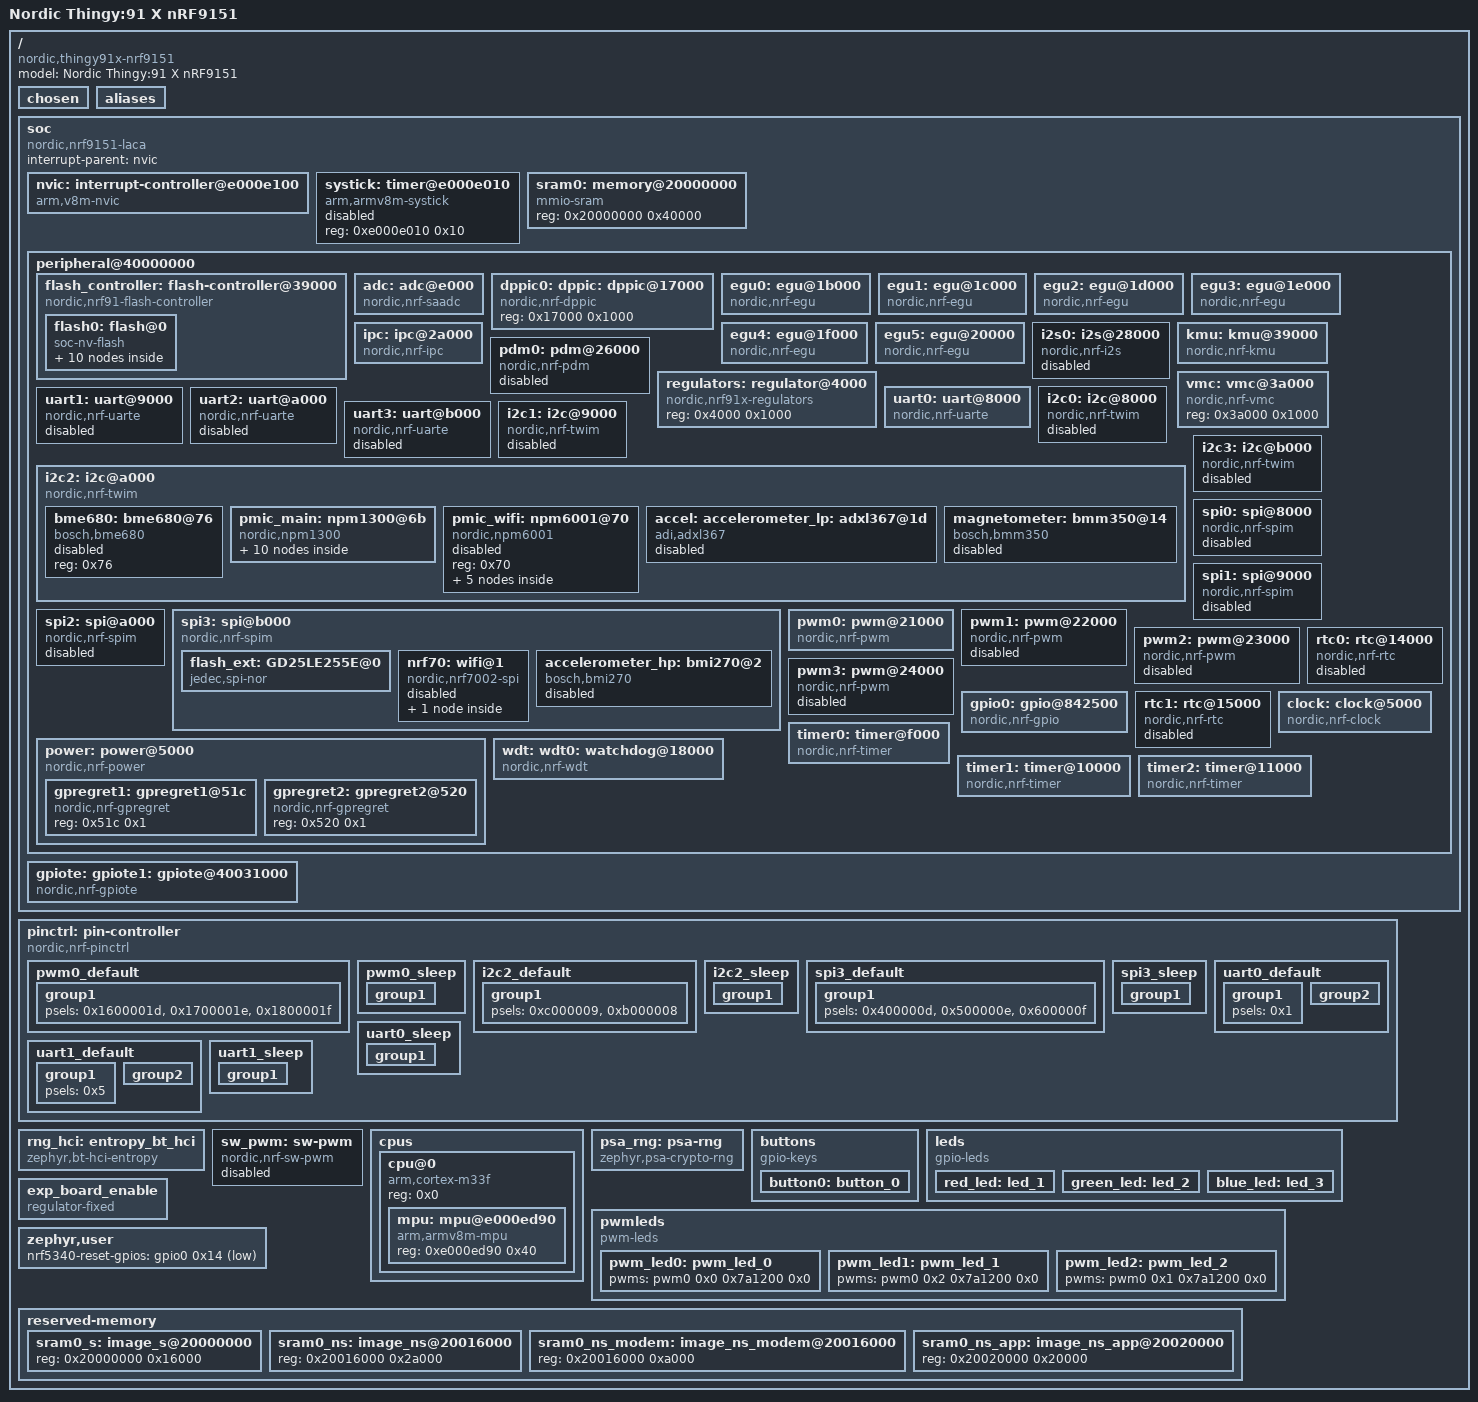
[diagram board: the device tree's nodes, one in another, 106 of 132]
/dts-v1/;

/* node '/' defined in zephyr/dts/common/skeleton.dtsi:9 */
/ {
	#address-cells = < 0x1 >;                /* in zephyr/dts/common/skeleton.dtsi:10 */
	#size-cells = < 0x1 >;                   /* in zephyr/dts/common/skeleton.dtsi:11 */
	model = "Nordic Thingy:91 X nRF9151";    /* in nrf/boards/nordic/thingy91x/thingy91x_nrf9151_common.dtsi:10 */
	compatible = "nordic,thingy91x-nrf9151"; /* in nrf/boards/nordic/thingy91x/thingy91x_nrf9151_common.dtsi:11 */

	/* node '/chosen' defined in zephyr/dts/common/skeleton.dtsi:12 */
	chosen {
		zephyr,entropy = &psa_rng;                   /* in zephyr/dts/arm/nordic/nrf91ns.dtsi:31 */
		zephyr,flash-controller = &flash_controller; /* in zephyr/dts/arm/nordic/nrf91ns.dtsi:32 */
		zephyr,console = &uart0;                     /* in nrf/boards/nordic/thingy91x/thingy91x_nrf9151_common.dtsi:14 */
		zephyr,shell-uart = &uart0;                  /* in nrf/boards/nordic/thingy91x/thingy91x_nrf9151_common.dtsi:15 */
		zephyr,uart-mcumgr = &uart0;                 /* in nrf/boards/nordic/thingy91x/thingy91x_nrf9151_common.dtsi:16 */
		nordic,pm-ext-flash = &flash_ext;            /* in nrf/boards/nordic/thingy91x/thingy91x_nrf9151_common.dtsi:17 */
		zephyr,flash = &flash0;                      /* in nrf/boards/nordic/thingy91x/thingy91x_nrf9151_ns.dts:12 */
		zephyr,sram = &sram0_ns_app;                 /* in nrf/boards/nordic/thingy91x/thingy91x_nrf9151_ns.dts:13 */
		zephyr,code-partition = &slot0_ns_partition; /* in nrf/boards/nordic/thingy91x/thingy91x_nrf9151_ns.dts:14 */
		zephyr,wifi = &nordic_wlan0;                 /* in nrf/boards/nordic/thingy91x/thingy91x_nrf9151_ns.dts:15 */
	};

	/* node '/aliases' defined in zephyr/dts/common/skeleton.dtsi:13 */
	aliases {
		sw0 = &button0;             /* in nrf/boards/nordic/thingy91x/thingy91x_nrf9151_common.dtsi:70 */
		led0 = &red_led;            /* in nrf/boards/nordic/thingy91x/thingy91x_nrf9151_common.dtsi:71 */
		led1 = &green_led;          /* in nrf/boards/nordic/thingy91x/thingy91x_nrf9151_common.dtsi:72 */
		led2 = &blue_led;           /* in nrf/boards/nordic/thingy91x/thingy91x_nrf9151_common.dtsi:73 */
		pwm-led0 = &pwm_led0;       /* in nrf/boards/nordic/thingy91x/thingy91x_nrf9151_common.dtsi:74 */
		pwm-led1 = &pwm_led1;       /* in nrf/boards/nordic/thingy91x/thingy91x_nrf9151_common.dtsi:75 */
		pwm-led2 = &pwm_led2;       /* in nrf/boards/nordic/thingy91x/thingy91x_nrf9151_common.dtsi:76 */
		rgb-pwm = &pwm0;            /* in nrf/boards/nordic/thingy91x/thingy91x_nrf9151_common.dtsi:77 */
		mcuboot-button0 = &button0; /* in nrf/boards/nordic/thingy91x/thingy91x_nrf9151_common.dtsi:78 */
		spi-flash0 = &flash_ext;    /* in nrf/boards/nordic/thingy91x/thingy91x_nrf9151_common.dtsi:79 */
	};

	/* node '/soc' defined in zephyr/dts/arm/armv8-m.dtsi:6 */
	soc {
		#address-cells = < 0x1 >;           /* in zephyr/dts/arm/armv8-m.dtsi:7 */
		#size-cells = < 0x1 >;              /* in zephyr/dts/arm/armv8-m.dtsi:8 */
		compatible = "nordic,nrf9151-laca",
		             "nordic,nrf9120",
		             "nordic,nrf91",
		             "simple-bus";          /* in zephyr/dts/arm/nordic/nrf9151ns_laca.dtsi:20 */
		interrupt-parent = < &nvic >;       /* in zephyr/dts/arm/armv8-m.dtsi:10 */
		ranges;                             /* in zephyr/dts/arm/armv8-m.dtsi:11 */

		/* node '/soc/interrupt-controller@e000e100' defined in zephyr/dts/arm/armv8-m.dtsi:13 */
		nvic: interrupt-controller@e000e100 {
			#address-cells = < 0x1 >;            /* in zephyr/dts/arm/armv8-m.dtsi:14 */
			compatible = "arm,v8m-nvic";         /* in zephyr/dts/arm/armv8-m.dtsi:15 */
			reg = < 0xe000e100 0xc00 >;          /* in zephyr/dts/arm/armv8-m.dtsi:16 */
			interrupt-controller;                /* in zephyr/dts/arm/armv8-m.dtsi:17 */
			#interrupt-cells = < 0x2 >;          /* in zephyr/dts/arm/armv8-m.dtsi:18 */
			arm,num-irq-priority-bits = < 0x3 >; /* in zephyr/dts/arm/nordic/nrf91ns.dtsi:70 */
			phandle = < 0x1 >;                   /* in zephyr/dts/arm/armv8-m.dtsi:10 */
		};

		/* node '/soc/timer@e000e010' defined in zephyr/dts/arm/armv8-m.dtsi:21 */
		systick: timer@e000e010 {
			compatible = "arm,armv8m-systick"; /* in zephyr/dts/arm/armv8-m.dtsi:22 */
			reg = < 0xe000e010 0x10 >;         /* in zephyr/dts/arm/armv8-m.dtsi:23 */
			status = "disabled";               /* in zephyr/dts/arm/nordic/nrf91ns.dtsi:75 */
		};

		/* node '/soc/memory@20000000' defined in zephyr/dts/arm/nordic/nrf91ns.dtsi:36 */
		sram0: memory@20000000 {
			compatible = "mmio-sram";     /* in zephyr/dts/arm/nordic/nrf91ns.dtsi:37 */
			reg = < 0x20000000 0x40000 >; /* in zephyr/dts/arm/nordic/nrf9151ns_laca.dtsi:15 */
		};

		/* node '/soc/peripheral@40000000' defined in zephyr/dts/arm/nordic/nrf91ns.dtsi:40 */
		peripheral@40000000 {
			#address-cells = < 0x1 >;               /* in zephyr/dts/arm/nordic/nrf91ns.dtsi:41 */
			#size-cells = < 0x1 >;                  /* in zephyr/dts/arm/nordic/nrf91ns.dtsi:42 */
			ranges = < 0x0 0x40000000 0x10000000 >; /* in zephyr/dts/arm/nordic/nrf91ns.dtsi:43 */

			/* node '/soc/peripheral@40000000/flash-controller@39000' defined in zephyr/dts/arm/nordic/nrf91_peripherals.dtsi:7 */
			flash_controller: flash-controller@39000 {
				compatible = "nordic,nrf91-flash-controller"; /* in zephyr/dts/arm/nordic/nrf91_peripherals.dtsi:8 */
				reg = < 0x39000 0x1000 >;                     /* in zephyr/dts/arm/nordic/nrf91_peripherals.dtsi:9 */
				partial-erase;                                /* in zephyr/dts/arm/nordic/nrf91_peripherals.dtsi:10 */
				#address-cells = < 0x1 >;                     /* in zephyr/dts/arm/nordic/nrf91_peripherals.dtsi:12 */
				#size-cells = < 0x1 >;                        /* in zephyr/dts/arm/nordic/nrf91_peripherals.dtsi:13 */

				/* node '/soc/peripheral@40000000/flash-controller@39000/flash@0' defined in zephyr/dts/arm/nordic/nrf91_peripherals.dtsi:16 */
				flash0: flash@0 {
					compatible = "soc-nv-flash";   /* in zephyr/dts/arm/nordic/nrf91_peripherals.dtsi:17 */
					erase-block-size = < 0x1000 >; /* in zephyr/dts/arm/nordic/nrf91_peripherals.dtsi:18 */
					write-block-size = < 0x4 >;    /* in zephyr/dts/arm/nordic/nrf91_peripherals.dtsi:19 */
					reg = < 0x0 0x100000 >;        /* in zephyr/dts/arm/nordic/nrf9151ns_laca.dtsi:11 */

					/* node '/soc/peripheral@40000000/flash-controller@39000/flash@0/partitions' defined in zephyr/dts/vendor/nordic/nrf91xx_partition.dtsi:27 */
					partitions {
						compatible = "fixed-partitions"; /* in zephyr/dts/vendor/nordic/nrf91xx_partition.dtsi:28 */
						#address-cells = < 0x1 >;        /* in zephyr/dts/vendor/nordic/nrf91xx_partition.dtsi:29 */
						#size-cells = < 0x1 >;           /* in zephyr/dts/vendor/nordic/nrf91xx_partition.dtsi:30 */

						/* node '/soc/peripheral@40000000/flash-controller@39000/flash@0/partitions/partition@0' defined in zephyr/dts/vendor/nordic/nrf91xx_partition.dtsi:32 */
						boot_partition: partition@0 {
							label = "mcuboot";     /* in zephyr/dts/vendor/nordic/nrf91xx_partition.dtsi:33 */
							reg = < 0x0 0x10000 >; /* in zephyr/dts/vendor/nordic/nrf91xx_partition.dtsi:34 */
						};

						/* node '/soc/peripheral@40000000/flash-controller@39000/flash@0/partitions/partition@10000' defined in zephyr/dts/vendor/nordic/nrf91xx_partition.dtsi:37 */
						slot0_partition: partition@10000 {
							label = "image-0";         /* in zephyr/dts/vendor/nordic/nrf91xx_partition.dtsi:38 */
							reg = < 0x10000 0x40000 >; /* in zephyr/dts/vendor/nordic/nrf91xx_partition.dtsi:39 */
						};

						/* node '/soc/peripheral@40000000/flash-controller@39000/flash@0/partitions/partition@50000' defined in zephyr/dts/vendor/nordic/nrf91xx_partition.dtsi:42 */
						slot0_ns_partition: partition@50000 {
							label = "image-0-nonsecure"; /* in zephyr/dts/vendor/nordic/nrf91xx_partition.dtsi:43 */
							reg = < 0x50000 0x30000 >;   /* in zephyr/dts/vendor/nordic/nrf91xx_partition.dtsi:44 */
						};

						/* node '/soc/peripheral@40000000/flash-controller@39000/flash@0/partitions/partition@80000' defined in zephyr/dts/vendor/nordic/nrf91xx_partition.dtsi:47 */
						slot1_partition: partition@80000 {
							label = "image-1";         /* in zephyr/dts/vendor/nordic/nrf91xx_partition.dtsi:48 */
							reg = < 0x80000 0x40000 >; /* in zephyr/dts/vendor/nordic/nrf91xx_partition.dtsi:49 */
						};

						/* node '/soc/peripheral@40000000/flash-controller@39000/flash@0/partitions/partition@c0000' defined in zephyr/dts/vendor/nordic/nrf91xx_partition.dtsi:52 */
						slot1_ns_partition: partition@c0000 {
							label = "image-1-nonsecure"; /* in zephyr/dts/vendor/nordic/nrf91xx_partition.dtsi:53 */
							reg = < 0xc0000 0x30000 >;   /* in zephyr/dts/vendor/nordic/nrf91xx_partition.dtsi:54 */
						};

						/* node '/soc/peripheral@40000000/flash-controller@39000/flash@0/partitions/partition@f0000' defined in zephyr/dts/vendor/nordic/nrf91xx_partition.dtsi:57 */
						tfm_ps_partition: partition@f0000 {
							label = "tfm-ps";         /* in zephyr/dts/vendor/nordic/nrf91xx_partition.dtsi:58 */
							reg = < 0xf0000 0x4000 >; /* in zephyr/dts/vendor/nordic/nrf91xx_partition.dtsi:59 */
						};

						/* node '/soc/peripheral@40000000/flash-controller@39000/flash@0/partitions/partition@f4000' defined in zephyr/dts/vendor/nordic/nrf91xx_partition.dtsi:62 */
						tfm_its_partition: partition@f4000 {
							label = "tfm-its";        /* in zephyr/dts/vendor/nordic/nrf91xx_partition.dtsi:63 */
							reg = < 0xf4000 0x2000 >; /* in zephyr/dts/vendor/nordic/nrf91xx_partition.dtsi:64 */
						};

						/* node '/soc/peripheral@40000000/flash-controller@39000/flash@0/partitions/partition@f6000' defined in zephyr/dts/vendor/nordic/nrf91xx_partition.dtsi:67 */
						tfm_otp_partition: partition@f6000 {
							label = "tfm-otp";        /* in zephyr/dts/vendor/nordic/nrf91xx_partition.dtsi:68 */
							reg = < 0xf6000 0x2000 >; /* in zephyr/dts/vendor/nordic/nrf91xx_partition.dtsi:69 */
						};

						/* node '/soc/peripheral@40000000/flash-controller@39000/flash@0/partitions/partition@f8000' defined in zephyr/dts/vendor/nordic/nrf91xx_partition.dtsi:72 */
						storage_partition: partition@f8000 {
							label = "storage";        /* in zephyr/dts/vendor/nordic/nrf91xx_partition.dtsi:73 */
							reg = < 0xf8000 0x8000 >; /* in zephyr/dts/vendor/nordic/nrf91xx_partition.dtsi:74 */
						};
					};
				};
			};

			/* node '/soc/peripheral@40000000/adc@e000' defined in zephyr/dts/arm/nordic/nrf91_peripherals.dtsi:23 */
			adc: adc@e000 {
				compatible = "nordic,nrf-saadc"; /* in zephyr/dts/arm/nordic/nrf91_peripherals.dtsi:24 */
				reg = < 0xe000 0x1000 >;         /* in zephyr/dts/arm/nordic/nrf91_peripherals.dtsi:25 */
				interrupts = < 0xe 0x1 >;        /* in zephyr/dts/arm/nordic/nrf91_peripherals.dtsi:26 */
				status = "okay";                 /* in nrf/boards/nordic/thingy91x/thingy91x_nrf9151_common.dtsi:84 */
				#io-channel-cells = < 0x1 >;     /* in zephyr/dts/arm/nordic/nrf91_peripherals.dtsi:28 */
				zephyr,pm-device-runtime-auto;   /* in zephyr/dts/arm/nordic/nrf91_peripherals.dtsi:29 */
			};

			/* node '/soc/peripheral@40000000/dppic@17000' defined in zephyr/dts/arm/nordic/nrf91_peripherals.dtsi:32 */
			dppic0: dppic: dppic@17000 {
				compatible = "nordic,nrf-dppic"; /* in zephyr/dts/arm/nordic/nrf91_peripherals.dtsi:33 */
				reg = < 0x17000 0x1000 >;        /* in zephyr/dts/arm/nordic/nrf91_peripherals.dtsi:34 */
				status = "okay";                 /* in zephyr/dts/arm/nordic/nrf91_peripherals.dtsi:35 */
			};

			/* node '/soc/peripheral@40000000/egu@1b000' defined in zephyr/dts/arm/nordic/nrf91_peripherals.dtsi:38 */
			egu0: egu@1b000 {
				compatible = "nordic,nrf-egu"; /* in zephyr/dts/arm/nordic/nrf91_peripherals.dtsi:39 */
				reg = < 0x1b000 0x1000 >;      /* in zephyr/dts/arm/nordic/nrf91_peripherals.dtsi:40 */
				interrupts = < 0x1b 0x1 >;     /* in zephyr/dts/arm/nordic/nrf91_peripherals.dtsi:41 */
				status = "okay";               /* in zephyr/dts/arm/nordic/nrf91_peripherals.dtsi:42 */
			};

			/* node '/soc/peripheral@40000000/egu@1c000' defined in zephyr/dts/arm/nordic/nrf91_peripherals.dtsi:45 */
			egu1: egu@1c000 {
				compatible = "nordic,nrf-egu"; /* in zephyr/dts/arm/nordic/nrf91_peripherals.dtsi:46 */
				reg = < 0x1c000 0x1000 >;      /* in zephyr/dts/arm/nordic/nrf91_peripherals.dtsi:47 */
				interrupts = < 0x1c 0x1 >;     /* in zephyr/dts/arm/nordic/nrf91_peripherals.dtsi:48 */
				status = "okay";               /* in zephyr/dts/arm/nordic/nrf91_peripherals.dtsi:49 */
			};

			/* node '/soc/peripheral@40000000/egu@1d000' defined in zephyr/dts/arm/nordic/nrf91_peripherals.dtsi:52 */
			egu2: egu@1d000 {
				compatible = "nordic,nrf-egu"; /* in zephyr/dts/arm/nordic/nrf91_peripherals.dtsi:53 */
				reg = < 0x1d000 0x1000 >;      /* in zephyr/dts/arm/nordic/nrf91_peripherals.dtsi:54 */
				interrupts = < 0x1d 0x1 >;     /* in zephyr/dts/arm/nordic/nrf91_peripherals.dtsi:55 */
				status = "okay";               /* in zephyr/dts/arm/nordic/nrf91_peripherals.dtsi:56 */
			};

			/* node '/soc/peripheral@40000000/egu@1e000' defined in zephyr/dts/arm/nordic/nrf91_peripherals.dtsi:59 */
			egu3: egu@1e000 {
				compatible = "nordic,nrf-egu"; /* in zephyr/dts/arm/nordic/nrf91_peripherals.dtsi:60 */
				reg = < 0x1e000 0x1000 >;      /* in zephyr/dts/arm/nordic/nrf91_peripherals.dtsi:61 */
				interrupts = < 0x1e 0x1 >;     /* in zephyr/dts/arm/nordic/nrf91_peripherals.dtsi:62 */
				status = "okay";               /* in zephyr/dts/arm/nordic/nrf91_peripherals.dtsi:63 */
			};

			/* node '/soc/peripheral@40000000/egu@1f000' defined in zephyr/dts/arm/nordic/nrf91_peripherals.dtsi:66 */
			egu4: egu@1f000 {
				compatible = "nordic,nrf-egu"; /* in zephyr/dts/arm/nordic/nrf91_peripherals.dtsi:67 */
				reg = < 0x1f000 0x1000 >;      /* in zephyr/dts/arm/nordic/nrf91_peripherals.dtsi:68 */
				interrupts = < 0x1f 0x1 >;     /* in zephyr/dts/arm/nordic/nrf91_peripherals.dtsi:69 */
				status = "okay";               /* in zephyr/dts/arm/nordic/nrf91_peripherals.dtsi:70 */
			};

			/* node '/soc/peripheral@40000000/egu@20000' defined in zephyr/dts/arm/nordic/nrf91_peripherals.dtsi:73 */
			egu5: egu@20000 {
				compatible = "nordic,nrf-egu"; /* in zephyr/dts/arm/nordic/nrf91_peripherals.dtsi:74 */
				reg = < 0x20000 0x1000 >;      /* in zephyr/dts/arm/nordic/nrf91_peripherals.dtsi:75 */
				interrupts = < 0x20 0x1 >;     /* in zephyr/dts/arm/nordic/nrf91_peripherals.dtsi:76 */
				status = "okay";               /* in zephyr/dts/arm/nordic/nrf91_peripherals.dtsi:77 */
			};

			/* node '/soc/peripheral@40000000/ipc@2a000' defined in zephyr/dts/arm/nordic/nrf91_peripherals.dtsi:80 */
			ipc: ipc@2a000 {
				compatible = "nordic,nrf-ipc"; /* in zephyr/dts/arm/nordic/nrf91_peripherals.dtsi:81 */
				reg = < 0x2a000 0x1000 >;      /* in zephyr/dts/arm/nordic/nrf91_peripherals.dtsi:82 */
				interrupts = < 0x2a 0x1 >;     /* in zephyr/dts/arm/nordic/nrf91_peripherals.dtsi:83 */
				status = "okay";               /* in zephyr/dts/arm/nordic/nrf91_peripherals.dtsi:84 */
			};

			/* node '/soc/peripheral@40000000/i2s@28000' defined in zephyr/dts/arm/nordic/nrf91_peripherals.dtsi:87 */
			i2s0: i2s@28000 {
				compatible = "nordic,nrf-i2s"; /* in zephyr/dts/arm/nordic/nrf91_peripherals.dtsi:88 */
				#address-cells = < 0x1 >;      /* in zephyr/dts/arm/nordic/nrf91_peripherals.dtsi:89 */
				#size-cells = < 0x0 >;         /* in zephyr/dts/arm/nordic/nrf91_peripherals.dtsi:90 */
				reg = < 0x28000 0x1000 >;      /* in zephyr/dts/arm/nordic/nrf91_peripherals.dtsi:91 */
				interrupts = < 0x28 0x1 >;     /* in zephyr/dts/arm/nordic/nrf91_peripherals.dtsi:92 */
				status = "disabled";           /* in zephyr/dts/arm/nordic/nrf91_peripherals.dtsi:93 */
			};

			/* node '/soc/peripheral@40000000/kmu@39000' defined in zephyr/dts/arm/nordic/nrf91_peripherals.dtsi:96 */
			kmu: kmu@39000 {
				compatible = "nordic,nrf-kmu"; /* in zephyr/dts/arm/nordic/nrf91_peripherals.dtsi:97 */
				reg = < 0x39000 0x1000 >;      /* in zephyr/dts/arm/nordic/nrf91_peripherals.dtsi:98 */
				interrupts = < 0x39 0x1 >;     /* in zephyr/dts/arm/nordic/nrf91_peripherals.dtsi:99 */
				status = "okay";               /* in zephyr/dts/arm/nordic/nrf91_peripherals.dtsi:100 */
			};

			/* node '/soc/peripheral@40000000/pdm@26000' defined in zephyr/dts/arm/nordic/nrf91_peripherals.dtsi:103 */
			pdm0: pdm@26000 {
				compatible = "nordic,nrf-pdm"; /* in zephyr/dts/arm/nordic/nrf91_peripherals.dtsi:104 */
				reg = < 0x26000 0x1000 >;      /* in zephyr/dts/arm/nordic/nrf91_peripherals.dtsi:105 */
				interrupts = < 0x26 0x1 >;     /* in zephyr/dts/arm/nordic/nrf91_peripherals.dtsi:106 */
				status = "disabled";           /* in zephyr/dts/arm/nordic/nrf91_peripherals.dtsi:107 */
			};

			/* node '/soc/peripheral@40000000/regulator@4000' defined in zephyr/dts/arm/nordic/nrf91_peripherals.dtsi:110 */
			regulators: regulator@4000 {
				compatible = "nordic,nrf91x-regulators"; /* in zephyr/dts/arm/nordic/nrf91_peripherals.dtsi:111 */
				reg = < 0x4000 0x1000 >;                 /* in zephyr/dts/arm/nordic/nrf91_peripherals.dtsi:112 */
				status = "okay";                         /* in zephyr/dts/arm/nordic/nrf91_peripherals.dtsi:113 */
			};

			/* node '/soc/peripheral@40000000/vmc@3a000' defined in zephyr/dts/arm/nordic/nrf91_peripherals.dtsi:116 */
			vmc: vmc@3a000 {
				compatible = "nordic,nrf-vmc"; /* in zephyr/dts/arm/nordic/nrf91_peripherals.dtsi:117 */
				reg = < 0x3a000 0x1000 >;      /* in zephyr/dts/arm/nordic/nrf91_peripherals.dtsi:118 */
				status = "okay";               /* in zephyr/dts/arm/nordic/nrf91_peripherals.dtsi:119 */
			};

			/* node '/soc/peripheral@40000000/uart@8000' defined in zephyr/dts/arm/nordic/nrf91_peripherals.dtsi:122 */
			uart0: uart@8000 {
				compatible = "nordic,nrf-uarte"; /* in nrf/boards/nordic/thingy91x/thingy91x_nrf9151_common.dtsi:164 */
				reg = < 0x8000 0x1000 >;         /* in zephyr/dts/arm/nordic/nrf91_peripherals.dtsi:124 */
				interrupts = < 0x8 0x1 >;        /* in zephyr/dts/arm/nordic/nrf91_peripherals.dtsi:125 */
				status = "okay";                 /* in nrf/boards/nordic/thingy91x/thingy91x_nrf9151_common.dtsi:166 */
				current-speed = < 0x1c200 >;     /* in nrf/boards/nordic/thingy91x/thingy91x_nrf9151_common.dtsi:165 */
				pinctrl-0 = < &uart0_default >;  /* in nrf/boards/nordic/thingy91x/thingy91x_nrf9151_common.dtsi:167 */
				pinctrl-1 = < &uart0_sleep >;    /* in nrf/boards/nordic/thingy91x/thingy91x_nrf9151_common.dtsi:168 */
				pinctrl-names = "default",
				                "sleep";         /* in nrf/boards/nordic/thingy91x/thingy91x_nrf9151_common.dtsi:169 */
			};

			/* node '/soc/peripheral@40000000/uart@9000' defined in zephyr/dts/arm/nordic/nrf91_peripherals.dtsi:129 */
			uart1: uart@9000 {
				compatible = "nordic,nrf-uarte"; /* in zephyr/dts/arm/nordic/nrf91_peripherals.dtsi:130 */
				reg = < 0x9000 0x1000 >;         /* in zephyr/dts/arm/nordic/nrf91_peripherals.dtsi:131 */
				interrupts = < 0x9 0x1 >;        /* in zephyr/dts/arm/nordic/nrf91_peripherals.dtsi:132 */
				status = "disabled";             /* in nrf/boards/nordic/thingy91x/thingy91x_nrf9151_ns.dts:22 */
				current-speed = < 0xf4240 >;     /* in nrf/boards/nordic/thingy91x/thingy91x_nrf9151_common.dtsi:173 */
				pinctrl-0 = < &uart1_default >;  /* in nrf/boards/nordic/thingy91x/thingy91x_nrf9151_common.dtsi:175 */
				pinctrl-1 = < &uart1_sleep >;    /* in nrf/boards/nordic/thingy91x/thingy91x_nrf9151_common.dtsi:176 */
				pinctrl-names = "default",
				                "sleep";         /* in nrf/boards/nordic/thingy91x/thingy91x_nrf9151_common.dtsi:177 */
			};

			/* node '/soc/peripheral@40000000/uart@a000' defined in zephyr/dts/arm/nordic/nrf91_peripherals.dtsi:136 */
			uart2: uart@a000 {
				compatible = "nordic,nrf-uarte"; /* in zephyr/dts/arm/nordic/nrf91_peripherals.dtsi:137 */
				reg = < 0xa000 0x1000 >;         /* in zephyr/dts/arm/nordic/nrf91_peripherals.dtsi:138 */
				interrupts = < 0xa 0x1 >;        /* in zephyr/dts/arm/nordic/nrf91_peripherals.dtsi:139 */
				status = "disabled";             /* in zephyr/dts/arm/nordic/nrf91_peripherals.dtsi:140 */
			};

			/* node '/soc/peripheral@40000000/uart@b000' defined in zephyr/dts/arm/nordic/nrf91_peripherals.dtsi:143 */
			uart3: uart@b000 {
				compatible = "nordic,nrf-uarte"; /* in zephyr/dts/arm/nordic/nrf91_peripherals.dtsi:144 */
				reg = < 0xb000 0x1000 >;         /* in zephyr/dts/arm/nordic/nrf91_peripherals.dtsi:145 */
				interrupts = < 0xb 0x1 >;        /* in zephyr/dts/arm/nordic/nrf91_peripherals.dtsi:146 */
				status = "disabled";             /* in zephyr/dts/arm/nordic/nrf91_peripherals.dtsi:147 */
			};

			/* node '/soc/peripheral@40000000/i2c@8000' defined in zephyr/dts/arm/nordic/nrf91_peripherals.dtsi:150 */
			i2c0: i2c@8000 {
				compatible = "nordic,nrf-twim"; /* in zephyr/dts/arm/nordic/nrf91_peripherals.dtsi:156 */
				#address-cells = < 0x1 >;       /* in zephyr/dts/arm/nordic/nrf91_peripherals.dtsi:157 */
				#size-cells = < 0x0 >;          /* in zephyr/dts/arm/nordic/nrf91_peripherals.dtsi:158 */
				reg = < 0x8000 0x1000 >;        /* in zephyr/dts/arm/nordic/nrf91_peripherals.dtsi:159 */
				interrupts = < 0x8 0x1 >;       /* in zephyr/dts/arm/nordic/nrf91_peripherals.dtsi:160 */
				easydma-maxcnt-bits = < 0xd >;  /* in zephyr/dts/arm/nordic/nrf91_peripherals.dtsi:161 */
				status = "disabled";            /* in zephyr/dts/arm/nordic/nrf91_peripherals.dtsi:162 */
				zephyr,pm-device-runtime-auto;  /* in zephyr/dts/arm/nordic/nrf91_peripherals.dtsi:163 */
			};

			/* node '/soc/peripheral@40000000/i2c@9000' defined in zephyr/dts/arm/nordic/nrf91_peripherals.dtsi:166 */
			i2c1: i2c@9000 {
				compatible = "nordic,nrf-twim"; /* in zephyr/dts/arm/nordic/nrf91_peripherals.dtsi:172 */
				#address-cells = < 0x1 >;       /* in zephyr/dts/arm/nordic/nrf91_peripherals.dtsi:173 */
				#size-cells = < 0x0 >;          /* in zephyr/dts/arm/nordic/nrf91_peripherals.dtsi:174 */
				reg = < 0x9000 0x1000 >;        /* in zephyr/dts/arm/nordic/nrf91_peripherals.dtsi:175 */
				interrupts = < 0x9 0x1 >;       /* in zephyr/dts/arm/nordic/nrf91_peripherals.dtsi:176 */
				easydma-maxcnt-bits = < 0xd >;  /* in zephyr/dts/arm/nordic/nrf91_peripherals.dtsi:177 */
				status = "disabled";            /* in zephyr/dts/arm/nordic/nrf91_peripherals.dtsi:178 */
				zephyr,pm-device-runtime-auto;  /* in zephyr/dts/arm/nordic/nrf91_peripherals.dtsi:179 */
			};

			/* node '/soc/peripheral@40000000/i2c@a000' defined in zephyr/dts/arm/nordic/nrf91_peripherals.dtsi:182 */
			i2c2: i2c@a000 {
				compatible = "nordic,nrf-twim"; /* in nrf/boards/nordic/thingy91x/thingy91x_common.dtsi:10 */
				#address-cells = < 0x1 >;       /* in zephyr/dts/arm/nordic/nrf91_peripherals.dtsi:189 */
				#size-cells = < 0x0 >;          /* in zephyr/dts/arm/nordic/nrf91_peripherals.dtsi:190 */
				reg = < 0xa000 0x1000 >;        /* in zephyr/dts/arm/nordic/nrf91_peripherals.dtsi:191 */
				interrupts = < 0xa 0x1 >;       /* in zephyr/dts/arm/nordic/nrf91_peripherals.dtsi:192 */
				easydma-maxcnt-bits = < 0xd >;  /* in zephyr/dts/arm/nordic/nrf91_peripherals.dtsi:193 */
				status = "okay";                /* in nrf/boards/nordic/thingy91x/thingy91x_nrf9151_common.dtsi:129 */
				zephyr,pm-device-runtime-auto;  /* in zephyr/dts/arm/nordic/nrf91_peripherals.dtsi:195 */
				clock-frequency = < 0x186a0 >;  /* in nrf/boards/nordic/thingy91x/thingy91x_common.dtsi:12 */
				pinctrl-0 = < &i2c2_default >;  /* in nrf/boards/nordic/thingy91x/thingy91x_common.dtsi:14 */
				pinctrl-1 = < &i2c2_sleep >;    /* in nrf/boards/nordic/thingy91x/thingy91x_common.dtsi:15 */
				pinctrl-names = "default",
				                "sleep";        /* in nrf/boards/nordic/thingy91x/thingy91x_common.dtsi:16 */

				/* node '/soc/peripheral@40000000/i2c@a000/bme680@76' defined in nrf/boards/nordic/thingy91x/thingy91x_common.dtsi:18 */
				bme680: bme680@76 {
					status = "disabled";         /* in nrf/boards/nordic/thingy91x/thingy91x_common.dtsi:19 */
					compatible = "bosch,bme680"; /* in nrf/boards/nordic/thingy91x/thingy91x_common.dtsi:20 */
					reg = < 0x76 >;              /* in nrf/boards/nordic/thingy91x/thingy91x_common.dtsi:21 */
				};

				/* node '/soc/peripheral@40000000/i2c@a000/npm1300@6b' defined in nrf/boards/nordic/thingy91x/thingy91x_common.dtsi:24 */
				pmic_main: npm1300@6b {
					compatible = "nordic,npm1300";       /* in nrf/boards/nordic/thingy91x/thingy91x_common.dtsi:25 */
					status = "okay";                     /* in nrf/boards/nordic/thingy91x/thingy91x_nrf9151_common.dtsi:139 */
					pmic-int-pin = < 0x3 >;              /* in nrf/boards/nordic/thingy91x/thingy91x_common.dtsi:27 */
					reg = < 0x6b >;                      /* in nrf/boards/nordic/thingy91x/thingy91x_common.dtsi:28 */
					host-int-gpios = < &gpio0 0x2 0x0 >; /* in nrf/boards/nordic/thingy91x/thingy91x_nrf9151_common.dtsi:106 */

					/* node '/soc/peripheral@40000000/i2c@a000/npm1300@6b/npm1300_gpios' defined in nrf/boards/nordic/thingy91x/thingy91x_common.dtsi:30 */
					gpios_pmic: npm1300_gpios {
						compatible = "nordic,npm1300-gpio"; /* in nrf/boards/nordic/thingy91x/thingy91x_common.dtsi:31 */
						status = "okay";                    /* in nrf/boards/nordic/thingy91x/thingy91x_nrf9151_common.dtsi:141 */
						gpio-controller;                    /* in nrf/boards/nordic/thingy91x/thingy91x_common.dtsi:33 */
						#gpio-cells = < 0x2 >;              /* in nrf/boards/nordic/thingy91x/thingy91x_common.dtsi:34 */
						ngpios = < 0x5 >;                   /* in nrf/boards/nordic/thingy91x/thingy91x_common.dtsi:35 */

						/* node '/soc/peripheral@40000000/i2c@a000/npm1300@6b/npm1300_gpios/GPIO0' defined in nrf/boards/nordic/thingy91x/thingy91x_common.dtsi:36 */
						npm13_button: GPIO0 {
							gpio-hog;            /* in nrf/boards/nordic/thingy91x/thingy91x_common.dtsi:37 */
							gpios = < 0x0 0x0 >; /* in nrf/boards/nordic/thingy91x/thingy91x_common.dtsi:38 */
						};

						/* node '/soc/peripheral@40000000/i2c@a000/npm1300@6b/npm1300_gpios/GPIO1' defined in nrf/boards/nordic/thingy91x/thingy91x_common.dtsi:41 */
						ldsw_rf_fe_sr_en: GPIO1 {
							gpio-hog;             /* in nrf/boards/nordic/thingy91x/thingy91x_common.dtsi:42 */
							output-low;           /* in nrf/boards/nordic/thingy91x/thingy91x_common.dtsi:43 */
							gpios = < 0x1 0x17 >; /* in nrf/boards/nordic/thingy91x/thingy91x_common.dtsi:44 */
						};

						/* node '/soc/peripheral@40000000/i2c@a000/npm1300@6b/npm1300_gpios/GPIO2' defined in nrf/boards/nordic/thingy91x/thingy91x_common.dtsi:46 */
						power_switch: GPIO2 {
							gpio-hog;            /* in nrf/boards/nordic/thingy91x/thingy91x_common.dtsi:47 */
							gpios = < 0x2 0x0 >; /* in nrf/boards/nordic/thingy91x/thingy91x_common.dtsi:48 */
						};

						/* node '/soc/peripheral@40000000/i2c@a000/npm1300@6b/npm1300_gpios/GPIO4' defined in nrf/boards/nordic/thingy91x/thingy91x_common.dtsi:50 */
						npm6001_ready: GPIO4 {
							gpio-hog;            /* in nrf/boards/nordic/thingy91x/thingy91x_common.dtsi:51 */
							gpios = < 0x4 0x0 >; /* in nrf/boards/nordic/thingy91x/thingy91x_common.dtsi:52 */
						};
					};

					/* node '/soc/peripheral@40000000/i2c@a000/npm1300@6b/regulators' defined in nrf/boards/nordic/thingy91x/thingy91x_common.dtsi:56 */
					regulators {
						compatible = "nordic,npm1300-regulator"; /* in nrf/boards/nordic/thingy91x/thingy91x_common.dtsi:57 */
						status = "okay";                         /* in nrf/boards/nordic/thingy91x/thingy91x_nrf9151_common.dtsi:144 */

						/* node '/soc/peripheral@40000000/i2c@a000/npm1300@6b/regulators/BUCK2' defined in nrf/boards/nordic/thingy91x/thingy91x_common.dtsi:60 */
						reg_3v3: BUCK2 {
							regulator-min-microvolt = < 0x325aa0 >; /* in nrf/boards/nordic/thingy91x/thingy91x_common.dtsi:61 */
							regulator-max-microvolt = < 0x325aa0 >; /* in nrf/boards/nordic/thingy91x/thingy91x_common.dtsi:62 */
							enable-gpio-config = < 0x2 0x0 >;       /* in nrf/boards/nordic/thingy91x/thingy91x_common.dtsi:63 */
						};

						/* node '/soc/peripheral@40000000/i2c@a000/npm1300@6b/regulators/LDO1' defined in nrf/boards/nordic/thingy91x/thingy91x_common.dtsi:66 */
						ldsw_nPM6001_en: LDO1 {
							regulator-initial-mode = < 0x3 >;  /* in nrf/boards/nordic/thingy91x/thingy91x_common.dtsi:67 */
							regulator-allowed-modes = < 0x3 >; /* in nrf/boards/nordic/thingy91x/thingy91x_common.dtsi:68 */
							regulator-boot-off;                /* in nrf/boards/nordic/thingy91x/thingy91x_common.dtsi:69 */
						};

						/* node '/soc/peripheral@40000000/i2c@a000/npm1300@6b/regulators/LDO2' defined in nrf/boards/nordic/thingy91x/thingy91x_common.dtsi:72 */
						ldsw_sensors: LDO2 {
							regulator-initial-mode = < 0x3 >;  /* in nrf/boards/nordic/thingy91x/thingy91x_common.dtsi:73 */
							regulator-allowed-modes = < 0x3 >; /* in nrf/boards/nordic/thingy91x/thingy91x_common.dtsi:74 */
							regulator-boot-on;                 /* in nrf/boards/nordic/thingy91x/thingy91x_common.dtsi:75 */
						};
					};

					/* node '/soc/peripheral@40000000/i2c@a000/npm1300@6b/charger' defined in nrf/boards/nordic/thingy91x/thingy91x_common.dtsi:79 */
					npm1300_charger: charger {
						compatible = "nordic,npm1300-charger";     /* in nrf/boards/nordic/thingy91x/thingy91x_common.dtsi:80 */
						status = "okay";                           /* in nrf/boards/nordic/thingy91x/thingy91x_nrf9151_common.dtsi:147 */
						vbus-limit-microamp = < 0x7a120 >;         /* in nrf/boards/nordic/thingy91x/thingy91x_common.dtsi:82 */
						term-microvolt = < 0x401640 >;             /* in nrf/boards/nordic/thingy91x/thingy91x_common.dtsi:84 */
						current-microamp = < 0xa4cb8 >;            /* in nrf/boards/nordic/thingy91x/thingy91x_common.dtsi:85 */
						dischg-limit-microamp = < 0xf4240 >;       /* in nrf/boards/nordic/thingy91x/thingy91x_common.dtsi:86 */
						thermistor-cold-millidegrees = < 0x0 >;    /* in nrf/boards/nordic/thingy91x/thingy91x_common.dtsi:87 */
						thermistor-cool-millidegrees = < 0x0 >;    /* in nrf/boards/nordic/thingy91x/thingy91x_common.dtsi:88 */
						thermistor-warm-millidegrees = < 0xafc8 >; /* in nrf/boards/nordic/thingy91x/thingy91x_common.dtsi:89 */
						thermistor-hot-millidegrees = < 0xafc8 >;  /* in nrf/boards/nordic/thingy91x/thingy91x_common.dtsi:90 */
						thermistor-ohms = < 0x2710 >;              /* in nrf/boards/nordic/thingy91x/thingy91x_common.dtsi:91 */
						thermistor-beta = < 0xd6b >;               /* in nrf/boards/nordic/thingy91x/thingy91x_common.dtsi:92 */
						charging-enable;                           /* in nrf/boards/nordic/thingy91x/thingy91x_common.dtsi:93 */
					};
				};

				/* node '/soc/peripheral@40000000/i2c@a000/npm6001@70' defined in nrf/boards/nordic/thingy91x/thingy91x_common.dtsi:97 */
				pmic_wifi: npm6001@70 {
					status = "disabled";           /* in nrf/boards/nordic/thingy91x/thingy91x_common.dtsi:99 */
					compatible = "nordic,npm6001"; /* in nrf/boards/nordic/thingy91x/thingy91x_common.dtsi:101 */
					reg = < 0x70 >;                /* in nrf/boards/nordic/thingy91x/thingy91x_common.dtsi:102 */

					/* node '/soc/peripheral@40000000/i2c@a000/npm6001@70/regulators' defined in nrf/boards/nordic/thingy91x/thingy91x_common.dtsi:104 */
					regulators {
						compatible = "nordic,npm6001-regulator"; /* in nrf/boards/nordic/thingy91x/thingy91x_common.dtsi:105 */
						status = "disabled";                     /* in nrf/boards/nordic/thingy91x/thingy91x_common.dtsi:106 */

						/* node '/soc/peripheral@40000000/i2c@a000/npm6001@70/regulators/BUCK0' defined in nrf/boards/nordic/thingy91x/thingy91x_common.dtsi:107 */
						pmic_wifi_buck0: BUCK0 {
							regulator-boot-off; /* in nrf/boards/nordic/thingy91x/thingy91x_common.dtsi:108 */
						};

						/* node '/soc/peripheral@40000000/i2c@a000/npm6001@70/regulators/BUCK1' defined in nrf/boards/nordic/thingy91x/thingy91x_common.dtsi:110 */
						pmic_wifi_buck1: BUCK1 {
							regulator-boot-off; /* in nrf/boards/nordic/thingy91x/thingy91x_common.dtsi:111 */
						};

						/* node '/soc/peripheral@40000000/i2c@a000/npm6001@70/regulators/BUCK2' defined in nrf/boards/nordic/thingy91x/thingy91x_common.dtsi:113 */
						pmic_wifi_buck2: BUCK2 {
							regulator-boot-off; /* in nrf/boards/nordic/thingy91x/thingy91x_common.dtsi:114 */
						};

						/* node '/soc/peripheral@40000000/i2c@a000/npm6001@70/regulators/BUCK3' defined in nrf/boards/nordic/thingy91x/thingy91x_common.dtsi:117 */
						reg_wifi: BUCK3 {
							regulator-min-microvolt = < 0x325aa0 >; /* in nrf/boards/nordic/thingy91x/thingy91x_common.dtsi:118 */
							regulator-max-microvolt = < 0x325aa0 >; /* in nrf/boards/nordic/thingy91x/thingy91x_common.dtsi:119 */
							regulator-initial-mode = < 0x0 >;       /* in nrf/boards/nordic/thingy91x/thingy91x_common.dtsi:120 */
							regulator-boot-on;                      /* in nrf/boards/nordic/thingy91x/thingy91x_common.dtsi:121 */
						};
					};
				};

				/* node '/soc/peripheral@40000000/i2c@a000/adxl367@1d' defined in nrf/boards/nordic/thingy91x/thingy91x_common.dtsi:126 */
				accel: accelerometer_lp: adxl367@1d {
					status = "disabled";             /* in nrf/boards/nordic/thingy91x/thingy91x_common.dtsi:127 */
					compatible = "adi,adxl367";      /* in nrf/boards/nordic/thingy91x/thingy91x_common.dtsi:128 */
					odr = < 0x3 >;                   /* in nrf/boards/nordic/thingy91x/thingy91x_common.dtsi:129 */
					reg = < 0x1d >;                  /* in nrf/boards/nordic/thingy91x/thingy91x_common.dtsi:130 */
					int1-gpios = < &gpio0 0xb 0x0 >; /* in nrf/boards/nordic/thingy91x/thingy91x_nrf9151_common.dtsi:115 */
				};

				/* node '/soc/peripheral@40000000/i2c@a000/bmm350@14' defined in nrf/boards/nordic/thingy91x/thingy91x_common.dtsi:133 */
				magnetometer: bmm350@14 {
					status = "disabled";             /* in nrf/boards/nordic/thingy91x/thingy91x_common.dtsi:134 */
					compatible = "bosch,bmm350";     /* in nrf/boards/nordic/thingy91x/thingy91x_common.dtsi:135 */
					reg = < 0x14 >;                  /* in nrf/boards/nordic/thingy91x/thingy91x_common.dtsi:136 */
					drdy-gpios = < &gpio0 0x7 0x1 >; /* in nrf/boards/nordic/thingy91x/thingy91x_nrf9151_common.dtsi:112 */
				};
			};

			/* node '/soc/peripheral@40000000/i2c@b000' defined in zephyr/dts/arm/nordic/nrf91_peripherals.dtsi:198 */
			i2c3: i2c@b000 {
				compatible = "nordic,nrf-twim"; /* in zephyr/dts/arm/nordic/nrf91_peripherals.dtsi:204 */
				#address-cells = < 0x1 >;       /* in zephyr/dts/arm/nordic/nrf91_peripherals.dtsi:205 */
				#size-cells = < 0x0 >;          /* in zephyr/dts/arm/nordic/nrf91_peripherals.dtsi:206 */
				reg = < 0xb000 0x1000 >;        /* in zephyr/dts/arm/nordic/nrf91_peripherals.dtsi:207 */
				interrupts = < 0xb 0x1 >;       /* in zephyr/dts/arm/nordic/nrf91_peripherals.dtsi:208 */
				easydma-maxcnt-bits = < 0xd >;  /* in zephyr/dts/arm/nordic/nrf91_peripherals.dtsi:209 */
				status = "disabled";            /* in zephyr/dts/arm/nordic/nrf91_peripherals.dtsi:210 */
				zephyr,pm-device-runtime-auto;  /* in zephyr/dts/arm/nordic/nrf91_peripherals.dtsi:211 */
			};

			/* node '/soc/peripheral@40000000/spi@8000' defined in zephyr/dts/arm/nordic/nrf91_peripherals.dtsi:214 */
			spi0: spi@8000 {
				compatible = "nordic,nrf-spim"; /* in zephyr/dts/arm/nordic/nrf91_peripherals.dtsi:220 */
				#address-cells = < 0x1 >;       /* in zephyr/dts/arm/nordic/nrf91_peripherals.dtsi:221 */
				#size-cells = < 0x0 >;          /* in zephyr/dts/arm/nordic/nrf91_peripherals.dtsi:222 */
				reg = < 0x8000 0x1000 >;        /* in zephyr/dts/arm/nordic/nrf91_peripherals.dtsi:223 */
				interrupts = < 0x8 0x1 >;       /* in zephyr/dts/arm/nordic/nrf91_peripherals.dtsi:224 */
				max-frequency = < 0x7a1200 >;   /* in zephyr/dts/arm/nordic/nrf91_peripherals.dtsi:225 */
				easydma-maxcnt-bits = < 0xd >;  /* in zephyr/dts/arm/nordic/nrf91_peripherals.dtsi:226 */
				status = "disabled";            /* in zephyr/dts/arm/nordic/nrf91_peripherals.dtsi:227 */
			};

			/* node '/soc/peripheral@40000000/spi@9000' defined in zephyr/dts/arm/nordic/nrf91_peripherals.dtsi:230 */
			spi1: spi@9000 {
				compatible = "nordic,nrf-spim"; /* in zephyr/dts/arm/nordic/nrf91_peripherals.dtsi:236 */
				#address-cells = < 0x1 >;       /* in zephyr/dts/arm/nordic/nrf91_peripherals.dtsi:237 */
				#size-cells = < 0x0 >;          /* in zephyr/dts/arm/nordic/nrf91_peripherals.dtsi:238 */
				reg = < 0x9000 0x1000 >;        /* in zephyr/dts/arm/nordic/nrf91_peripherals.dtsi:239 */
				interrupts = < 0x9 0x1 >;       /* in zephyr/dts/arm/nordic/nrf91_peripherals.dtsi:240 */
				max-frequency = < 0x7a1200 >;   /* in zephyr/dts/arm/nordic/nrf91_peripherals.dtsi:241 */
				easydma-maxcnt-bits = < 0xd >;  /* in zephyr/dts/arm/nordic/nrf91_peripherals.dtsi:242 */
				status = "disabled";            /* in zephyr/dts/arm/nordic/nrf91_peripherals.dtsi:243 */
			};

			/* node '/soc/peripheral@40000000/spi@a000' defined in zephyr/dts/arm/nordic/nrf91_peripherals.dtsi:246 */
			spi2: spi@a000 {
				compatible = "nordic,nrf-spim"; /* in zephyr/dts/arm/nordic/nrf91_peripherals.dtsi:252 */
				#address-cells = < 0x1 >;       /* in zephyr/dts/arm/nordic/nrf91_peripherals.dtsi:253 */
				#size-cells = < 0x0 >;          /* in zephyr/dts/arm/nordic/nrf91_peripherals.dtsi:254 */
				reg = < 0xa000 0x1000 >;        /* in zephyr/dts/arm/nordic/nrf91_peripherals.dtsi:255 */
				interrupts = < 0xa 0x1 >;       /* in zephyr/dts/arm/nordic/nrf91_peripherals.dtsi:256 */
				max-frequency = < 0x7a1200 >;   /* in zephyr/dts/arm/nordic/nrf91_peripherals.dtsi:257 */
				easydma-maxcnt-bits = < 0xd >;  /* in zephyr/dts/arm/nordic/nrf91_peripherals.dtsi:258 */
				status = "disabled";            /* in zephyr/dts/arm/nordic/nrf91_peripherals.dtsi:259 */
			};

			/* node '/soc/peripheral@40000000/spi@b000' defined in zephyr/dts/arm/nordic/nrf91_peripherals.dtsi:262 */
			spi3: spi@b000 {
				compatible = "nordic,nrf-spim"; /* in nrf/boards/nordic/thingy91x/thingy91x_common.dtsi:141 */
				#address-cells = < 0x1 >;       /* in zephyr/dts/arm/nordic/nrf91_peripherals.dtsi:269 */
				#size-cells = < 0x0 >;          /* in zephyr/dts/arm/nordic/nrf91_peripherals.dtsi:270 */
				reg = < 0xb000 0x1000 >;        /* in zephyr/dts/arm/nordic/nrf91_peripherals.dtsi:271 */
				interrupts = < 0xb 0x1 >;       /* in zephyr/dts/arm/nordic/nrf91_peripherals.dtsi:272 */
				max-frequency = < 0x7a1200 >;   /* in zephyr/dts/arm/nordic/nrf91_peripherals.dtsi:273 */
				easydma-maxcnt-bits = < 0xd >;  /* in zephyr/dts/arm/nordic/nrf91_peripherals.dtsi:274 */
				status = "okay";                /* in nrf/boards/nordic/thingy91x/thingy91x_nrf9151_common.dtsi:132 */
				pinctrl-0 = < &spi3_default >;  /* in nrf/boards/nordic/thingy91x/thingy91x_common.dtsi:144 */
				pinctrl-1 = < &spi3_sleep >;    /* in nrf/boards/nordic/thingy91x/thingy91x_common.dtsi:145 */
				pinctrl-names = "default",
				                "sleep";        /* in nrf/boards/nordic/thingy91x/thingy91x_common.dtsi:146 */
				cs-gpios = < &gpio0 0xc 0x1 >,
				           < &gpio0 0x11 0x1 >,
				           < &gpio0 0xa 0x1 >;  /* in nrf/boards/nordic/thingy91x/thingy91x_nrf9151_common.dtsi:133 */

				/* node '/soc/peripheral@40000000/spi@b000/GD25LE255E@0' defined in nrf/boards/nordic/thingy91x/thingy91x_common.dtsi:148 */
				flash_ext: GD25LE255E@0 {
					compatible = "jedec,spi-nor";                                                                                                                                                                                   /* in nrf/boards/nordic/thingy91x/thingy91x_common.dtsi:149 */
					status = "okay";                                                                                                                                                                                                /* in nrf/boards/nordic/thingy91x/thingy91x_nrf9151_common.dtsi:119 */
					reg = < 0x0 >;                                                                                                                                                                                                  /* in nrf/boards/nordic/thingy91x/thingy91x_common.dtsi:151 */
					spi-max-frequency = < 0x7a1200 >;                                                                                                                                                                               /* in nrf/boards/nordic/thingy91x/thingy91x_common.dtsi:152 */
					size = < 0x10000000 >;                                                                                                                                                                                          /* in nrf/boards/nordic/thingy91x/thingy91x_common.dtsi:153 */
					has-dpd;                                                                                                                                                                                                        /* in nrf/boards/nordic/thingy91x/thingy91x_common.dtsi:154 */
					t-enter-dpd = < 0xbb8 >;                                                                                                                                                                                        /* in nrf/boards/nordic/thingy91x/thingy91x_common.dtsi:155 */
					t-exit-dpd = < 0x4e20 >;                                                                                                                                                                                        /* in nrf/boards/nordic/thingy91x/thingy91x_common.dtsi:156 */
					sfdp-bfp = [ E5 20 F3 FF FF FF FF 0F 44 EB 08 6B 08 3B 42 BB FE FF FF FF FF FF 00 FF FF FF 42 EB 0C 20 0F 52 10 D8 00 FF D4 31 A5 FE 84 DF 14 4F EC 62 16 33 7A 75 7A 75 04 B3 D5 5C 19 06 14 00 08 50 00 01 ]; /* in nrf/boards/nordic/thingy91x/thingy91x_common.dtsi:157 */
					jedec-id = [ C8 60 19 ];                                                                                                                                                                                        /* in nrf/boards/nordic/thingy91x/thingy91x_common.dtsi:161 */
				};

				/* node '/soc/peripheral@40000000/spi@b000/wifi@1' defined in nrf/boards/nordic/thingy91x/thingy91x_common.dtsi:164 */
				nrf70: wifi@1 {
					compatible = "nordic,nrf7002-spi";       /* in nrf/boards/nordic/thingy91x/thingy91x_common.dtsi:165 */
					status = "disabled";                     /* in nrf/boards/nordic/thingy91x/thingy91x_common.dtsi:166 */
					reg = < 0x1 >;                           /* in nrf/boards/nordic/thingy91x/thingy91x_common.dtsi:167 */
					spi-max-frequency = < 0x7a1200 >;        /* in nrf/boards/nordic/thingy91x/thingy91x_common.dtsi:168 */
					iovdd-ctrl-gpios = < &gpio0 0x1b 0x20 >; /* in nrf/boards/nordic/thingy91x/thingy91x_nrf9151_common.dtsi:123 */
					bucken-gpios = < &gpio0 0x1c 0x20 >;     /* in nrf/boards/nordic/thingy91x/thingy91x_nrf9151_common.dtsi:124 */
					host-irq-gpios = < &gpio0 0x10 0x0 >;    /* in nrf/boards/nordic/thingy91x/thingy91x_nrf9151_common.dtsi:125 */
					wifi-max-tx-pwr-2g-dsss = < 0x15 >;      /* in nrf/boards/nordic/thingy91x/thingy91x_common.dtsi:178 */
					wifi-max-tx-pwr-2g-mcs0 = < 0x10 >;      /* in nrf/boards/nordic/thingy91x/thingy91x_common.dtsi:179 */
					wifi-max-tx-pwr-2g-mcs7 = < 0x10 >;      /* in nrf/boards/nordic/thingy91x/thingy91x_common.dtsi:180 */
					wifi-max-tx-pwr-5g-low-mcs0 = < 0x9 >;   /* in nrf/boards/nordic/thingy91x/thingy91x_common.dtsi:181 */
					wifi-max-tx-pwr-5g-low-mcs7 = < 0x9 >;   /* in nrf/boards/nordic/thingy91x/thingy91x_common.dtsi:182 */
					wifi-max-tx-pwr-5g-mid-mcs0 = < 0xb >;   /* in nrf/boards/nordic/thingy91x/thingy91x_common.dtsi:183 */
					wifi-max-tx-pwr-5g-mid-mcs7 = < 0xb >;   /* in nrf/boards/nordic/thingy91x/thingy91x_common.dtsi:184 */
					wifi-max-tx-pwr-5g-high-mcs0 = < 0xd >;  /* in nrf/boards/nordic/thingy91x/thingy91x_common.dtsi:185 */
					wifi-max-tx-pwr-5g-high-mcs7 = < 0xd >;  /* in nrf/boards/nordic/thingy91x/thingy91x_common.dtsi:186 */

					/* node '/soc/peripheral@40000000/spi@b000/wifi@1/wlan0' defined in nrf/boards/nordic/thingy91x/thingy91x_common.dtsi:174 */
					nordic_wlan0: wlan0 {
						compatible = "nordic,wlan"; /* in nrf/boards/nordic/thingy91x/thingy91x_common.dtsi:175 */
					};
				};

				/* node '/soc/peripheral@40000000/spi@b000/bmi270@2' defined in nrf/boards/nordic/thingy91x/thingy91x_common.dtsi:189 */
				accelerometer_hp: bmi270@2 {
					compatible = "bosch,bmi270";      /* in nrf/boards/nordic/thingy91x/thingy91x_common.dtsi:190 */
					status = "disabled";              /* in nrf/boards/nordic/thingy91x/thingy91x_common.dtsi:191 */
					reg = < 0x2 >;                    /* in nrf/boards/nordic/thingy91x/thingy91x_common.dtsi:192 */
					spi-max-frequency = < 0x989680 >; /* in nrf/boards/nordic/thingy91x/thingy91x_common.dtsi:193 */
					irq-gpios = < &gpio0 0x6 0x1 >;   /* in nrf/boards/nordic/thingy91x/thingy91x_nrf9151_common.dtsi:109 */
				};
			};

			/* node '/soc/peripheral@40000000/pwm@21000' defined in zephyr/dts/arm/nordic/nrf91_peripherals.dtsi:278 */
			pwm0: pwm@21000 {
				compatible = "nordic,nrf-pwm"; /* in zephyr/dts/arm/nordic/nrf91_peripherals.dtsi:279 */
				reg = < 0x21000 0x1000 >;      /* in zephyr/dts/arm/nordic/nrf91_peripherals.dtsi:280 */
				interrupts = < 0x21 0x1 >;     /* in zephyr/dts/arm/nordic/nrf91_peripherals.dtsi:281 */
				status = "okay";               /* in nrf/boards/nordic/thingy91x/thingy91x_nrf9151_common.dtsi:99 */
				#pwm-cells = < 0x3 >;          /* in zephyr/dts/arm/nordic/nrf91_peripherals.dtsi:283 */
				pinctrl-0 = < &pwm0_default >; /* in nrf/boards/nordic/thingy91x/thingy91x_nrf9151_common.dtsi:100 */
				pinctrl-1 = < &pwm0_sleep >;   /* in nrf/boards/nordic/thingy91x/thingy91x_nrf9151_common.dtsi:101 */
				pinctrl-names = "default",
				                "sleep";       /* in nrf/boards/nordic/thingy91x/thingy91x_nrf9151_common.dtsi:102 */
				phandle = < 0xf >;             /* in nrf/boards/nordic/thingy91x/thingy91x_nrf9151_common.dtsi:48 */
			};

			/* node '/soc/peripheral@40000000/pwm@22000' defined in zephyr/dts/arm/nordic/nrf91_peripherals.dtsi:286 */
			pwm1: pwm@22000 {
				compatible = "nordic,nrf-pwm"; /* in zephyr/dts/arm/nordic/nrf91_peripherals.dtsi:287 */
				reg = < 0x22000 0x1000 >;      /* in zephyr/dts/arm/nordic/nrf91_peripherals.dtsi:288 */
				interrupts = < 0x22 0x1 >;     /* in zephyr/dts/arm/nordic/nrf91_peripherals.dtsi:289 */
				status = "disabled";           /* in zephyr/dts/arm/nordic/nrf91_peripherals.dtsi:290 */
				#pwm-cells = < 0x3 >;          /* in zephyr/dts/arm/nordic/nrf91_peripherals.dtsi:291 */
			};

			/* node '/soc/peripheral@40000000/pwm@23000' defined in zephyr/dts/arm/nordic/nrf91_peripherals.dtsi:294 */
			pwm2: pwm@23000 {
				compatible = "nordic,nrf-pwm"; /* in zephyr/dts/arm/nordic/nrf91_peripherals.dtsi:295 */
				reg = < 0x23000 0x1000 >;      /* in zephyr/dts/arm/nordic/nrf91_peripherals.dtsi:296 */
				interrupts = < 0x23 0x1 >;     /* in zephyr/dts/arm/nordic/nrf91_peripherals.dtsi:297 */
				status = "disabled";           /* in zephyr/dts/arm/nordic/nrf91_peripherals.dtsi:298 */
				#pwm-cells = < 0x3 >;          /* in zephyr/dts/arm/nordic/nrf91_peripherals.dtsi:299 */
			};

			/* node '/soc/peripheral@40000000/pwm@24000' defined in zephyr/dts/arm/nordic/nrf91_peripherals.dtsi:302 */
			pwm3: pwm@24000 {
				compatible = "nordic,nrf-pwm"; /* in zephyr/dts/arm/nordic/nrf91_peripherals.dtsi:303 */
				reg = < 0x24000 0x1000 >;      /* in zephyr/dts/arm/nordic/nrf91_peripherals.dtsi:304 */
				interrupts = < 0x24 0x1 >;     /* in zephyr/dts/arm/nordic/nrf91_peripherals.dtsi:305 */
				status = "disabled";           /* in zephyr/dts/arm/nordic/nrf91_peripherals.dtsi:306 */
				#pwm-cells = < 0x3 >;          /* in zephyr/dts/arm/nordic/nrf91_peripherals.dtsi:307 */
			};

			/* node '/soc/peripheral@40000000/gpio@842500' defined in zephyr/dts/arm/nordic/nrf91_peripherals.dtsi:310 */
			gpio0: gpio@842500 {
				compatible = "nordic,nrf-gpio";   /* in zephyr/dts/arm/nordic/nrf91_peripherals.dtsi:311 */
				gpio-controller;                  /* in zephyr/dts/arm/nordic/nrf91_peripherals.dtsi:312 */
				reg = < 0x842500 0x300 >;         /* in zephyr/dts/arm/nordic/nrf91_peripherals.dtsi:313 */
				#gpio-cells = < 0x2 >;            /* in zephyr/dts/arm/nordic/nrf91_peripherals.dtsi:314 */
				status = "okay";                  /* in nrf/boards/nordic/thingy91x/thingy91x_nrf9151_common.dtsi:92 */
				port = < 0x0 >;                   /* in zephyr/dts/arm/nordic/nrf91_peripherals.dtsi:316 */
				gpiote-instance = < &gpiote >;    /* in zephyr/dts/arm/nordic/nrf91_peripherals.dtsi:317 */
				sense-edge-mask = < 0xffffffff >; /* in nrf/boards/nordic/thingy91x/thingy91x_nrf9151_common.dtsi:94 */
				phandle = < 0x8 >;                /* in nrf/boards/nordic/thingy91x/thingy91x_nrf9151_common.dtsi:106 */
			};

			/* node '/soc/peripheral@40000000/rtc@14000' defined in zephyr/dts/arm/nordic/nrf91_peripherals.dtsi:320 */
			rtc0: rtc@14000 {
				compatible = "nordic,nrf-rtc"; /* in zephyr/dts/arm/nordic/nrf91_peripherals.dtsi:321 */
				reg = < 0x14000 0x1000 >;      /* in zephyr/dts/arm/nordic/nrf91_peripherals.dtsi:322 */
				cc-num = < 0x4 >;              /* in zephyr/dts/arm/nordic/nrf91_peripherals.dtsi:323 */
				interrupts = < 0x14 0x1 >;     /* in zephyr/dts/arm/nordic/nrf91_peripherals.dtsi:324 */
				status = "disabled";           /* in zephyr/dts/arm/nordic/nrf91_peripherals.dtsi:325 */
				clock-frequency = < 0x8000 >;  /* in zephyr/dts/arm/nordic/nrf91_peripherals.dtsi:326 */
				prescaler = < 0x1 >;           /* in zephyr/dts/arm/nordic/nrf91_peripherals.dtsi:327 */
			};

			/* node '/soc/peripheral@40000000/rtc@15000' defined in zephyr/dts/arm/nordic/nrf91_peripherals.dtsi:330 */
			rtc1: rtc@15000 {
				compatible = "nordic,nrf-rtc"; /* in zephyr/dts/arm/nordic/nrf91_peripherals.dtsi:331 */
				reg = < 0x15000 0x1000 >;      /* in zephyr/dts/arm/nordic/nrf91_peripherals.dtsi:332 */
				cc-num = < 0x4 >;              /* in zephyr/dts/arm/nordic/nrf91_peripherals.dtsi:333 */
				interrupts = < 0x15 0x1 >;     /* in zephyr/dts/arm/nordic/nrf91_peripherals.dtsi:334 */
				status = "disabled";           /* in zephyr/dts/arm/nordic/nrf91_peripherals.dtsi:335 */
				clock-frequency = < 0x8000 >;  /* in zephyr/dts/arm/nordic/nrf91_peripherals.dtsi:336 */
				prescaler = < 0x1 >;           /* in zephyr/dts/arm/nordic/nrf91_peripherals.dtsi:337 */
			};

			/* node '/soc/peripheral@40000000/clock@5000' defined in zephyr/dts/arm/nordic/nrf91_peripherals.dtsi:340 */
			clock: clock@5000 {
				compatible = "nordic,nrf-clock"; /* in zephyr/dts/arm/nordic/nrf91_peripherals.dtsi:341 */
				reg = < 0x5000 0x1000 >;         /* in zephyr/dts/arm/nordic/nrf91_peripherals.dtsi:342 */
				interrupts = < 0x5 0x1 >;        /* in zephyr/dts/arm/nordic/nrf91_peripherals.dtsi:343 */
				status = "okay";                 /* in zephyr/dts/arm/nordic/nrf91_peripherals.dtsi:344 */
			};

			/* node '/soc/peripheral@40000000/power@5000' defined in zephyr/dts/arm/nordic/nrf91_peripherals.dtsi:347 */
			power: power@5000 {
				compatible = "nordic,nrf-power"; /* in zephyr/dts/arm/nordic/nrf91_peripherals.dtsi:348 */
				reg = < 0x5000 0x1000 >;         /* in zephyr/dts/arm/nordic/nrf91_peripherals.dtsi:349 */
				ranges = < 0x0 0x5000 0x1000 >;  /* in zephyr/dts/arm/nordic/nrf91_peripherals.dtsi:350 */
				interrupts = < 0x5 0x1 >;        /* in zephyr/dts/arm/nordic/nrf91_peripherals.dtsi:351 */
				status = "okay";                 /* in zephyr/dts/arm/nordic/nrf91_peripherals.dtsi:352 */
				#address-cells = < 0x1 >;        /* in zephyr/dts/arm/nordic/nrf91_peripherals.dtsi:353 */
				#size-cells = < 0x1 >;           /* in zephyr/dts/arm/nordic/nrf91_peripherals.dtsi:354 */

				/* node '/soc/peripheral@40000000/power@5000/gpregret1@51c' defined in zephyr/dts/arm/nordic/nrf91_peripherals.dtsi:356 */
				gpregret1: gpregret1@51c {
					#address-cells = < 0x1 >;           /* in zephyr/dts/arm/nordic/nrf91_peripherals.dtsi:357 */
					#size-cells = < 0x1 >;              /* in zephyr/dts/arm/nordic/nrf91_peripherals.dtsi:358 */
					compatible = "nordic,nrf-gpregret"; /* in zephyr/dts/arm/nordic/nrf91_peripherals.dtsi:359 */
					reg = < 0x51c 0x1 >;                /* in zephyr/dts/arm/nordic/nrf91_peripherals.dtsi:360 */
					status = "okay";                    /* in zephyr/dts/arm/nordic/nrf91_peripherals.dtsi:361 */
				};

				/* node '/soc/peripheral@40000000/power@5000/gpregret2@520' defined in zephyr/dts/arm/nordic/nrf91_peripherals.dtsi:364 */
				gpregret2: gpregret2@520 {
					#address-cells = < 0x1 >;           /* in zephyr/dts/arm/nordic/nrf91_peripherals.dtsi:365 */
					#size-cells = < 0x1 >;              /* in zephyr/dts/arm/nordic/nrf91_peripherals.dtsi:366 */
					compatible = "nordic,nrf-gpregret"; /* in zephyr/dts/arm/nordic/nrf91_peripherals.dtsi:367 */
					reg = < 0x520 0x1 >;                /* in zephyr/dts/arm/nordic/nrf91_peripherals.dtsi:368 */
					status = "okay";                    /* in zephyr/dts/arm/nordic/nrf91_peripherals.dtsi:369 */
				};
			};

			/* node '/soc/peripheral@40000000/watchdog@18000' defined in zephyr/dts/arm/nordic/nrf91_peripherals.dtsi:373 */
			wdt: wdt0: watchdog@18000 {
				compatible = "nordic,nrf-wdt"; /* in zephyr/dts/arm/nordic/nrf91_peripherals.dtsi:374 */
				reg = < 0x18000 0x1000 >;      /* in zephyr/dts/arm/nordic/nrf91_peripherals.dtsi:375 */
				interrupts = < 0x18 0x1 >;     /* in zephyr/dts/arm/nordic/nrf91_peripherals.dtsi:376 */
				status = "okay";               /* in zephyr/dts/arm/nordic/nrf91_peripherals.dtsi:377 */
			};

			/* node '/soc/peripheral@40000000/timer@f000' defined in zephyr/dts/arm/nordic/nrf91_peripherals.dtsi:380 */
			timer0: timer@f000 {
				compatible = "nordic,nrf-timer"; /* in zephyr/dts/arm/nordic/nrf91_peripherals.dtsi:381 */
				status = "okay";                 /* in nrf/boards/nordic/thingy91x/thingy91x_nrf9151_common.dtsi:152 */
				reg = < 0xf000 0x1000 >;         /* in zephyr/dts/arm/nordic/nrf91_peripherals.dtsi:383 */
				cc-num = < 0x6 >;                /* in zephyr/dts/arm/nordic/nrf91_peripherals.dtsi:384 */
				max-bit-width = < 0x20 >;        /* in zephyr/dts/arm/nordic/nrf91_peripherals.dtsi:385 */
				interrupts = < 0xf 0x1 >;        /* in zephyr/dts/arm/nordic/nrf91_peripherals.dtsi:386 */
				prescaler = < 0x0 >;             /* in zephyr/dts/arm/nordic/nrf91_peripherals.dtsi:387 */
			};

			/* node '/soc/peripheral@40000000/timer@10000' defined in zephyr/dts/arm/nordic/nrf91_peripherals.dtsi:390 */
			timer1: timer@10000 {
				compatible = "nordic,nrf-timer"; /* in zephyr/dts/arm/nordic/nrf91_peripherals.dtsi:391 */
				status = "okay";                 /* in nrf/boards/nordic/thingy91x/thingy91x_nrf9151_common.dtsi:156 */
				reg = < 0x10000 0x1000 >;        /* in zephyr/dts/arm/nordic/nrf91_peripherals.dtsi:393 */
				cc-num = < 0x6 >;                /* in zephyr/dts/arm/nordic/nrf91_peripherals.dtsi:394 */
				max-bit-width = < 0x20 >;        /* in zephyr/dts/arm/nordic/nrf91_peripherals.dtsi:395 */
				interrupts = < 0x10 0x1 >;       /* in zephyr/dts/arm/nordic/nrf91_peripherals.dtsi:396 */
				prescaler = < 0x0 >;             /* in zephyr/dts/arm/nordic/nrf91_peripherals.dtsi:397 */
				phandle = < 0xe >;               /* in zephyr/dts/vendor/nordic/nrf_common.dtsi:41 */
			};

			/* node '/soc/peripheral@40000000/timer@11000' defined in zephyr/dts/arm/nordic/nrf91_peripherals.dtsi:400 */
			timer2: timer@11000 {
				compatible = "nordic,nrf-timer"; /* in zephyr/dts/arm/nordic/nrf91_peripherals.dtsi:401 */
				status = "okay";                 /* in nrf/boards/nordic/thingy91x/thingy91x_nrf9151_common.dtsi:160 */
				reg = < 0x11000 0x1000 >;        /* in zephyr/dts/arm/nordic/nrf91_peripherals.dtsi:403 */
				cc-num = < 0x6 >;                /* in zephyr/dts/arm/nordic/nrf91_peripherals.dtsi:404 */
				max-bit-width = < 0x20 >;        /* in zephyr/dts/arm/nordic/nrf91_peripherals.dtsi:405 */
				interrupts = < 0x11 0x1 >;       /* in zephyr/dts/arm/nordic/nrf91_peripherals.dtsi:406 */
				prescaler = < 0x0 >;             /* in zephyr/dts/arm/nordic/nrf91_peripherals.dtsi:407 */
			};
		};

		/* node '/soc/gpiote@40031000' defined in zephyr/dts/arm/nordic/nrf91ns.dtsi:54 */
		gpiote: gpiote1: gpiote@40031000 {
			compatible = "nordic,nrf-gpiote"; /* in zephyr/dts/arm/nordic/nrf91ns.dtsi:55 */
			reg = < 0x40031000 0x1000 >;      /* in zephyr/dts/arm/nordic/nrf91ns.dtsi:56 */
			interrupts = < 0x31 0x5 >;        /* in zephyr/dts/arm/nordic/nrf91ns.dtsi:57 */
			status = "okay";                  /* in nrf/boards/nordic/thingy91x/thingy91x_nrf9151_common.dtsi:88 */
			instance = < 0x1 >;               /* in zephyr/dts/arm/nordic/nrf91ns.dtsi:59 */
			phandle = < 0xd >;                /* in zephyr/dts/arm/nordic/nrf91_peripherals.dtsi:317 */
		};
	};

	/* node '/pin-controller' defined in zephyr/dts/vendor/nordic/nrf_common.dtsi:25 */
	pinctrl: pin-controller {
		compatible = "nordic,nrf-pinctrl"; /* in zephyr/dts/vendor/nordic/nrf_common.dtsi:30 */

		/* node '/pin-controller/pwm0_default' defined in nrf/boards/nordic/thingy91x/thingy91x_nrf9151_common-pinctrl.dtsi:7 */
		pwm0_default: pwm0_default {
			phandle = < 0xb >; /* in nrf/boards/nordic/thingy91x/thingy91x_nrf9151_common.dtsi:100 */

			/* node '/pin-controller/pwm0_default/group1' defined in nrf/boards/nordic/thingy91x/thingy91x_nrf9151_common-pinctrl.dtsi:8 */
			group1 {
				psels = < 0x1600001d >,
				        < 0x1700001e >,
				        < 0x1800001f >; /* in nrf/boards/nordic/thingy91x/thingy91x_nrf9151_common-pinctrl.dtsi:9 */
			};
		};

		/* node '/pin-controller/pwm0_sleep' defined in nrf/boards/nordic/thingy91x/thingy91x_nrf9151_common-pinctrl.dtsi:15 */
		pwm0_sleep: pwm0_sleep {
			phandle = < 0xc >; /* in nrf/boards/nordic/thingy91x/thingy91x_nrf9151_common.dtsi:101 */

			/* node '/pin-controller/pwm0_sleep/group1' defined in nrf/boards/nordic/thingy91x/thingy91x_nrf9151_common-pinctrl.dtsi:16 */
			group1 {
				psels = < 0x1600001d >,
				        < 0x1700001e >,
				        < 0x1800001f >; /* in nrf/boards/nordic/thingy91x/thingy91x_nrf9151_common-pinctrl.dtsi:17 */
				low-power-enable;       /* in nrf/boards/nordic/thingy91x/thingy91x_nrf9151_common-pinctrl.dtsi:20 */
			};
		};

		/* node '/pin-controller/i2c2_default' defined in nrf/boards/nordic/thingy91x/thingy91x_nrf9151_common-pinctrl.dtsi:24 */
		i2c2_default: i2c2_default {
			phandle = < 0x6 >; /* in nrf/boards/nordic/thingy91x/thingy91x_common.dtsi:14 */

			/* node '/pin-controller/i2c2_default/group1' defined in nrf/boards/nordic/thingy91x/thingy91x_nrf9151_common-pinctrl.dtsi:25 */
			group1 {
				psels = < 0xc000009 >,
				        < 0xb000008 >; /* in nrf/boards/nordic/thingy91x/thingy91x_nrf9151_common-pinctrl.dtsi:26 */
			};
		};

		/* node '/pin-controller/i2c2_sleep' defined in nrf/boards/nordic/thingy91x/thingy91x_nrf9151_common-pinctrl.dtsi:31 */
		i2c2_sleep: i2c2_sleep {
			phandle = < 0x7 >; /* in nrf/boards/nordic/thingy91x/thingy91x_common.dtsi:15 */

			/* node '/pin-controller/i2c2_sleep/group1' defined in nrf/boards/nordic/thingy91x/thingy91x_nrf9151_common-pinctrl.dtsi:32 */
			group1 {
				psels = < 0xc000009 >,
				        < 0xb000008 >; /* in nrf/boards/nordic/thingy91x/thingy91x_nrf9151_common-pinctrl.dtsi:33 */
				low-power-enable;      /* in nrf/boards/nordic/thingy91x/thingy91x_nrf9151_common-pinctrl.dtsi:35 */
			};
		};

		/* node '/pin-controller/spi3_default' defined in nrf/boards/nordic/thingy91x/thingy91x_nrf9151_common-pinctrl.dtsi:39 */
		spi3_default: spi3_default {
			phandle = < 0x9 >; /* in nrf/boards/nordic/thingy91x/thingy91x_common.dtsi:144 */

			/* node '/pin-controller/spi3_default/group1' defined in nrf/boards/nordic/thingy91x/thingy91x_nrf9151_common-pinctrl.dtsi:40 */
			group1 {
				psels = < 0x400000d >,
				        < 0x500000e >,
				        < 0x600000f >; /* in nrf/boards/nordic/thingy91x/thingy91x_nrf9151_common-pinctrl.dtsi:41 */
			};
		};

		/* node '/pin-controller/spi3_sleep' defined in nrf/boards/nordic/thingy91x/thingy91x_nrf9151_common-pinctrl.dtsi:47 */
		spi3_sleep: spi3_sleep {
			phandle = < 0xa >; /* in nrf/boards/nordic/thingy91x/thingy91x_common.dtsi:145 */

			/* node '/pin-controller/spi3_sleep/group1' defined in nrf/boards/nordic/thingy91x/thingy91x_nrf9151_common-pinctrl.dtsi:48 */
			group1 {
				psels = < 0x400000d >,
				        < 0x500000e >,
				        < 0x600000f >; /* in nrf/boards/nordic/thingy91x/thingy91x_nrf9151_common-pinctrl.dtsi:49 */
				low-power-enable;      /* in nrf/boards/nordic/thingy91x/thingy91x_nrf9151_common-pinctrl.dtsi:52 */
			};
		};

		/* node '/pin-controller/uart0_default' defined in nrf/boards/nordic/thingy91x/thingy91x_nrf9151_common-pinctrl.dtsi:56 */
		uart0_default: uart0_default {
			phandle = < 0x2 >; /* in nrf/boards/nordic/thingy91x/thingy91x_nrf9151_common.dtsi:167 */

			/* node '/pin-controller/uart0_default/group1' defined in nrf/boards/nordic/thingy91x/thingy91x_nrf9151_common-pinctrl.dtsi:57 */
			group1 {
				psels = < 0x1 >; /* in nrf/boards/nordic/thingy91x/thingy91x_nrf9151_common-pinctrl.dtsi:58 */
			};

			/* node '/pin-controller/uart0_default/group2' defined in nrf/boards/nordic/thingy91x/thingy91x_nrf9151_common-pinctrl.dtsi:60 */
			group2 {
				psels = < 0x1000000 >; /* in nrf/boards/nordic/thingy91x/thingy91x_nrf9151_common-pinctrl.dtsi:61 */
				bias-pull-up;          /* in nrf/boards/nordic/thingy91x/thingy91x_nrf9151_common-pinctrl.dtsi:62 */
			};
		};

		/* node '/pin-controller/uart0_sleep' defined in nrf/boards/nordic/thingy91x/thingy91x_nrf9151_common-pinctrl.dtsi:66 */
		uart0_sleep: uart0_sleep {
			phandle = < 0x3 >; /* in nrf/boards/nordic/thingy91x/thingy91x_nrf9151_common.dtsi:168 */

			/* node '/pin-controller/uart0_sleep/group1' defined in nrf/boards/nordic/thingy91x/thingy91x_nrf9151_common-pinctrl.dtsi:67 */
			group1 {
				psels = < 0x1 >,
				        < 0x1000000 >; /* in nrf/boards/nordic/thingy91x/thingy91x_nrf9151_common-pinctrl.dtsi:68 */
				low-power-enable;      /* in nrf/boards/nordic/thingy91x/thingy91x_nrf9151_common-pinctrl.dtsi:70 */
			};
		};

		/* node '/pin-controller/uart1_default' defined in nrf/boards/nordic/thingy91x/thingy91x_nrf9151_common-pinctrl.dtsi:74 */
		uart1_default: uart1_default {
			phandle = < 0x4 >; /* in nrf/boards/nordic/thingy91x/thingy91x_nrf9151_common.dtsi:175 */

			/* node '/pin-controller/uart1_default/group1' defined in nrf/boards/nordic/thingy91x/thingy91x_nrf9151_common-pinctrl.dtsi:75 */
			group1 {
				psels = < 0x5 >; /* in nrf/boards/nordic/thingy91x/thingy91x_nrf9151_common-pinctrl.dtsi:76 */
			};

			/* node '/pin-controller/uart1_default/group2' defined in nrf/boards/nordic/thingy91x/thingy91x_nrf9151_common-pinctrl.dtsi:78 */
			group2 {
				psels = < 0x1000004 >; /* in nrf/boards/nordic/thingy91x/thingy91x_nrf9151_common-pinctrl.dtsi:79 */
				bias-pull-up;          /* in nrf/boards/nordic/thingy91x/thingy91x_nrf9151_common-pinctrl.dtsi:80 */
			};
		};

		/* node '/pin-controller/uart1_sleep' defined in nrf/boards/nordic/thingy91x/thingy91x_nrf9151_common-pinctrl.dtsi:84 */
		uart1_sleep: uart1_sleep {
			phandle = < 0x5 >; /* in nrf/boards/nordic/thingy91x/thingy91x_nrf9151_common.dtsi:176 */

			/* node '/pin-controller/uart1_sleep/group1' defined in nrf/boards/nordic/thingy91x/thingy91x_nrf9151_common-pinctrl.dtsi:85 */
			group1 {
				psels = < 0x5 >,
				        < 0x1000004 >; /* in nrf/boards/nordic/thingy91x/thingy91x_nrf9151_common-pinctrl.dtsi:86 */
				low-power-enable;      /* in nrf/boards/nordic/thingy91x/thingy91x_nrf9151_common-pinctrl.dtsi:88 */
			};
		};
	};

	/* node '/entropy_bt_hci' defined in zephyr/dts/vendor/nordic/nrf_common.dtsi:33 */
	rng_hci: entropy_bt_hci {
		compatible = "zephyr,bt-hci-entropy"; /* in zephyr/dts/vendor/nordic/nrf_common.dtsi:34 */
		status = "okay";                      /* in zephyr/dts/vendor/nordic/nrf_common.dtsi:35 */
	};

	/* node '/sw-pwm' defined in zephyr/dts/vendor/nordic/nrf_common.dtsi:38 */
	sw_pwm: sw-pwm {
		compatible = "nordic,nrf-sw-pwm"; /* in zephyr/dts/vendor/nordic/nrf_common.dtsi:39 */
		status = "disabled";              /* in zephyr/dts/vendor/nordic/nrf_common.dtsi:40 */
		generator = < &timer1 >;          /* in zephyr/dts/vendor/nordic/nrf_common.dtsi:41 */
		clock-prescaler = < 0x0 >;        /* in zephyr/dts/vendor/nordic/nrf_common.dtsi:42 */
		#pwm-cells = < 0x3 >;             /* in zephyr/dts/vendor/nordic/nrf_common.dtsi:43 */
	};

	/* node '/cpus' defined in zephyr/dts/arm/nordic/nrf91ns.dtsi:12 */
	cpus {
		#address-cells = < 0x1 >; /* in zephyr/dts/arm/nordic/nrf91ns.dtsi:13 */
		#size-cells = < 0x0 >;    /* in zephyr/dts/arm/nordic/nrf91ns.dtsi:14 */

		/* node '/cpus/cpu@0' defined in zephyr/dts/arm/nordic/nrf91ns.dtsi:16 */
		cpu@0 {
			device_type = "cpu";            /* in zephyr/dts/arm/nordic/nrf91ns.dtsi:17 */
			compatible = "arm,cortex-m33f"; /* in zephyr/dts/arm/nordic/nrf91ns.dtsi:18 */
			reg = < 0x0 >;                  /* in zephyr/dts/arm/nordic/nrf91ns.dtsi:19 */
			#address-cells = < 0x1 >;       /* in zephyr/dts/arm/nordic/nrf91ns.dtsi:20 */
			#size-cells = < 0x1 >;          /* in zephyr/dts/arm/nordic/nrf91ns.dtsi:21 */

			/* node '/cpus/cpu@0/mpu@e000ed90' defined in zephyr/dts/arm/nordic/nrf91ns.dtsi:23 */
			mpu: mpu@e000ed90 {
				compatible = "arm,armv8m-mpu"; /* in zephyr/dts/arm/nordic/nrf91ns.dtsi:24 */
				reg = < 0xe000ed90 0x40 >;     /* in zephyr/dts/arm/nordic/nrf91ns.dtsi:25 */
			};
		};
	};

	/* node '/psa-rng' defined in zephyr/dts/arm/nordic/nrf91ns.dtsi:63 */
	psa_rng: psa-rng {
		compatible = "zephyr,psa-crypto-rng"; /* in zephyr/dts/arm/nordic/nrf91ns.dtsi:64 */
		status = "okay";                      /* in zephyr/dts/arm/nordic/nrf91ns.dtsi:65 */
	};

	/* node '/buttons' defined in nrf/boards/nordic/thingy91x/thingy91x_nrf9151_common.dtsi:20 */
	buttons {
		compatible = "gpio-keys"; /* in nrf/boards/nordic/thingy91x/thingy91x_nrf9151_common.dtsi:21 */

		/* node '/buttons/button_0' defined in nrf/boards/nordic/thingy91x/thingy91x_nrf9151_common.dtsi:23 */
		button0: button_0 {
			gpios = < &gpio0 0x1a 0x11 >; /* in nrf/boards/nordic/thingy91x/thingy91x_nrf9151_common.dtsi:24 */
			label = "Button 1";           /* in nrf/boards/nordic/thingy91x/thingy91x_nrf9151_common.dtsi:25 */
		};
	};

	/* node '/leds' defined in nrf/boards/nordic/thingy91x/thingy91x_nrf9151_common.dtsi:29 */
	leds {
		compatible = "gpio-leds"; /* in nrf/boards/nordic/thingy91x/thingy91x_nrf9151_common.dtsi:30 */

		/* node '/leds/led_1' defined in nrf/boards/nordic/thingy91x/thingy91x_nrf9151_common.dtsi:31 */
		red_led: led_1 {
			gpios = < &gpio0 0x1d 0x0 >; /* in nrf/boards/nordic/thingy91x/thingy91x_nrf9151_common.dtsi:32 */
			label = "RGB red channel";   /* in nrf/boards/nordic/thingy91x/thingy91x_nrf9151_common.dtsi:33 */
		};

		/* node '/leds/led_2' defined in nrf/boards/nordic/thingy91x/thingy91x_nrf9151_common.dtsi:35 */
		green_led: led_2 {
			gpios = < &gpio0 0x1f 0x0 >; /* in nrf/boards/nordic/thingy91x/thingy91x_nrf9151_common.dtsi:36 */
			label = "RGB green channel"; /* in nrf/boards/nordic/thingy91x/thingy91x_nrf9151_common.dtsi:37 */
		};

		/* node '/leds/led_3' defined in nrf/boards/nordic/thingy91x/thingy91x_nrf9151_common.dtsi:39 */
		blue_led: led_3 {
			gpios = < &gpio0 0x1e 0x0 >; /* in nrf/boards/nordic/thingy91x/thingy91x_nrf9151_common.dtsi:40 */
			label = "RGB blue channel";  /* in nrf/boards/nordic/thingy91x/thingy91x_nrf9151_common.dtsi:41 */
		};
	};

	/* node '/pwmleds' defined in nrf/boards/nordic/thingy91x/thingy91x_nrf9151_common.dtsi:45 */
	pwmleds {
		compatible = "pwm-leds"; /* in nrf/boards/nordic/thingy91x/thingy91x_nrf9151_common.dtsi:46 */

		/* node '/pwmleds/pwm_led_0' defined in nrf/boards/nordic/thingy91x/thingy91x_nrf9151_common.dtsi:47 */
		pwm_led0: pwm_led_0 {
			pwms = < &pwm0 0x0 0x7a1200 0x0 >; /* in nrf/boards/nordic/thingy91x/thingy91x_nrf9151_common.dtsi:48 */
		};

		/* node '/pwmleds/pwm_led_1' defined in nrf/boards/nordic/thingy91x/thingy91x_nrf9151_common.dtsi:50 */
		pwm_led1: pwm_led_1 {
			pwms = < &pwm0 0x2 0x7a1200 0x0 >; /* in nrf/boards/nordic/thingy91x/thingy91x_nrf9151_common.dtsi:51 */
		};

		/* node '/pwmleds/pwm_led_2' defined in nrf/boards/nordic/thingy91x/thingy91x_nrf9151_common.dtsi:53 */
		pwm_led2: pwm_led_2 {
			pwms = < &pwm0 0x1 0x7a1200 0x0 >; /* in nrf/boards/nordic/thingy91x/thingy91x_nrf9151_common.dtsi:54 */
		};
	};

	/* node '/exp_board_enable' defined in nrf/boards/nordic/thingy91x/thingy91x_nrf9151_common.dtsi:59 */
	exp_board_enable: exp_board_enable {
		compatible = "regulator-fixed";      /* in nrf/boards/nordic/thingy91x/thingy91x_nrf9151_common.dtsi:60 */
		regulator-name = "exp_board_enable"; /* in nrf/boards/nordic/thingy91x/thingy91x_nrf9151_common.dtsi:61 */
		enable-gpios = < &gpio0 0x3 0x0 >;   /* in nrf/boards/nordic/thingy91x/thingy91x_nrf9151_common.dtsi:62 */
	};

	/* node '/zephyr,user' defined in nrf/boards/nordic/thingy91x/thingy91x_nrf9151_common.dtsi:65 */
	zephyr,user {
		nrf5340-reset-gpios = < &gpio0 0x14 0x1 >; /* in nrf/boards/nordic/thingy91x/thingy91x_nrf9151_common.dtsi:66 */
	};

	/* node '/reserved-memory' defined in zephyr/dts/vendor/nordic/nrf91xx_partition.dtsi:89 */
	reserved-memory {
		#address-cells = < 0x1 >; /* in zephyr/dts/vendor/nordic/nrf91xx_partition.dtsi:90 */
		#size-cells = < 0x1 >;    /* in zephyr/dts/vendor/nordic/nrf91xx_partition.dtsi:91 */
		ranges;                   /* in zephyr/dts/vendor/nordic/nrf91xx_partition.dtsi:92 */

		/* node '/reserved-memory/image_s@20000000' defined in zephyr/dts/vendor/nordic/nrf91xx_partition.dtsi:94 */
		sram0_s: image_s@20000000 {
			reg = < 0x20000000 0x16000 >; /* in zephyr/dts/vendor/nordic/nrf91xx_partition.dtsi:96 */
		};

		/* node '/reserved-memory/image_ns@20016000' defined in zephyr/dts/vendor/nordic/nrf91xx_partition.dtsi:99 */
		sram0_ns: image_ns@20016000 {
			reg = < 0x20016000 0x2a000 >; /* in zephyr/dts/vendor/nordic/nrf91xx_partition.dtsi:101 */
		};

		/* node '/reserved-memory/image_ns_modem@20016000' defined in zephyr/dts/vendor/nordic/nrf91xx_partition.dtsi:104 */
		sram0_ns_modem: image_ns_modem@20016000 {
			reg = < 0x20016000 0xa000 >; /* in zephyr/dts/vendor/nordic/nrf91xx_partition.dtsi:106 */
		};

		/* node '/reserved-memory/image_ns_app@20020000' defined in zephyr/dts/vendor/nordic/nrf91xx_partition.dtsi:109 */
		sram0_ns_app: image_ns_app@20020000 {
			reg = < 0x20020000 0x20000 >; /* in zephyr/dts/vendor/nordic/nrf91xx_partition.dtsi:111 */
		};
	};
};
